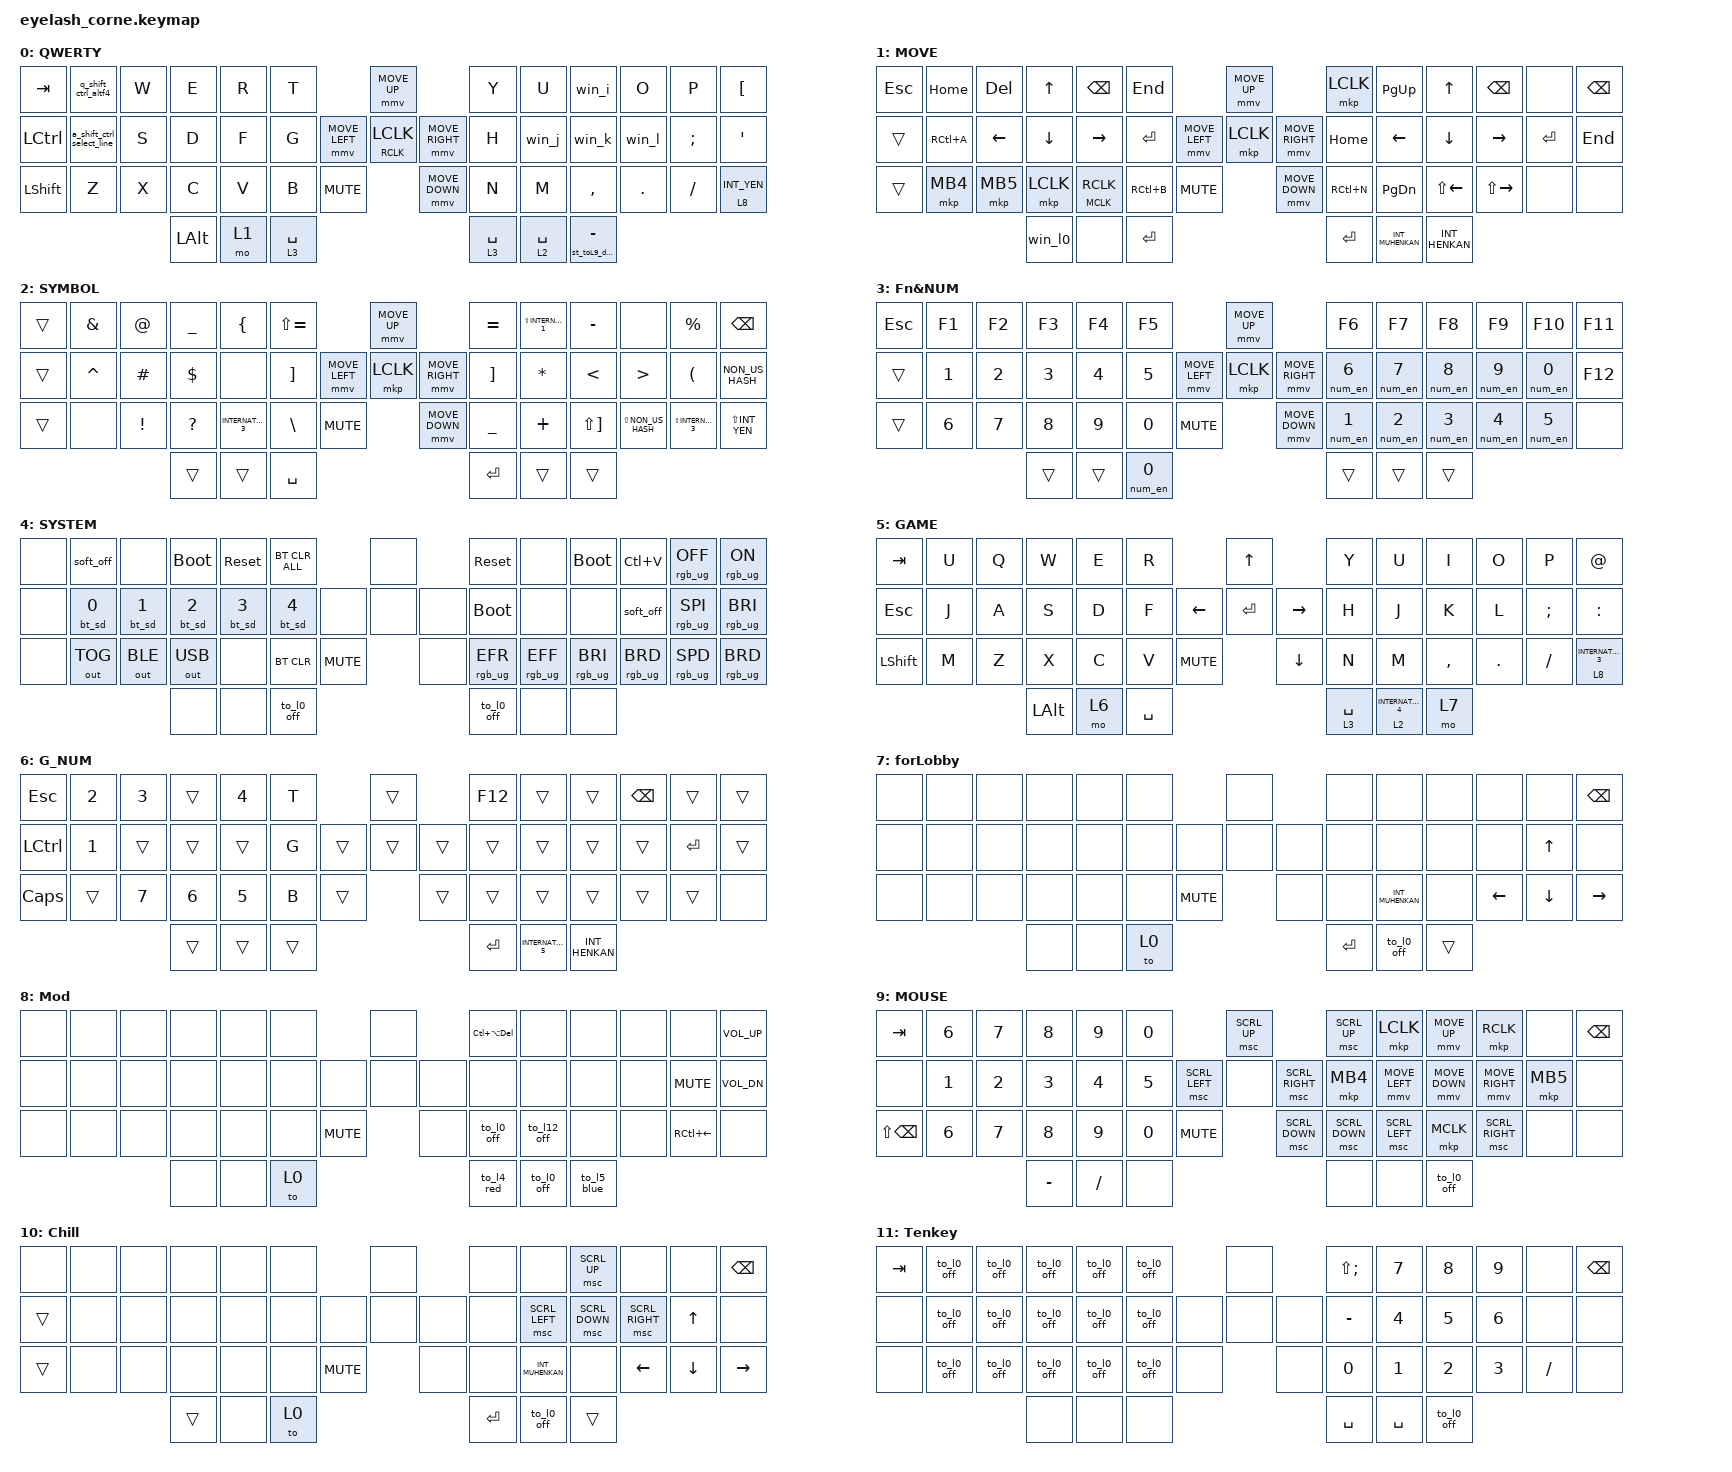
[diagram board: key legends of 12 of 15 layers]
#define ZMK_POINTING_DEFAULT_MOVE_VAL 1200  // 600
#define ZMK_POINTING_DEFAULT_SCRL_VAL 25    // 10
#define COLOR_RED RGB_COLOR_HSB(0, 100, 50)

#include <input/processors.dtsi>
#include <zephyr/dt-bindings/input/input-event-codes.h>
#include <behaviors/runtime-sensor-rotate.dtsi>
#include <behaviors.dtsi>
#include <dt-bindings/zmk/bt.h>
#include <dt-bindings/zmk/keys.h>
#include <dt-bindings/zmk/outputs.h>
#include <dt-bindings/zmk/pointing.h>
#include <dt-bindings/zmk/rgb.h>

&soft_off { hold-time-ms = <2000>; };

/ {
    macros {
        // Winキーを押した時にWinを保持したままLayer 0へ戻るマクロ

        win_l0: win_l0 {
            compatible = "zmk,behavior-macro";
            #binding-cells = <0>;
            wait-ms = <0>;
            tap-ms = <0>;
            bindings =
                <&macro_press>,
                <&kp LEFT_WIN &to 0>,
                <&macro_pause_for_release>,
                <&macro_release>,
                <&kp LEFT_WIN>;
        };

        // レイヤー4へ移動し、LEDをONにして赤くする

        to_l4_red: to_l4_red {
            compatible = "zmk,behavior-macro";
            #binding-cells = <0>;
            bindings = <&to 4 &rgb_ug COLOR_RED &rgb_ug RGB_ON>;
        };

        // レイヤー0(通常)に戻り、LEDをOFFにする

        to_l0_off: to_l0_off {
            compatible = "zmk,behavior-macro";
            #binding-cells = <0>;
            bindings = <&to 0 &rgb_ug RGB_OFF>;
        };

        // 【追加】レイヤー5へ移動し、LEDをONにして青くする（1秒後に自動消灯）

        to_l5_blue: to_l5_blue {
            compatible = "zmk,behavior-macro";
            #binding-cells = <0>;
            bindings = <&to 5>;
        };

        // 【追加】レイヤー7へ移動し、LEDをONにして紫にする（1秒後に自動消灯）

        to_l7_purple: to_l7_purple {
            compatible = "zmk,behavior-macro";
            #binding-cells = <0>;
            bindings = <&to 8>;

            // <&macro_wait_time 1000>,
            // <&rgb_ug RGB_OFF>;
        };

        // 【追加】レイヤー8へ移動し、LEDをONにしてオレンジにする

        to_l8_orange: to_l8_orange {
            compatible = "zmk,behavior-macro";
            #binding-cells = <0>;
            bindings = <&rgb_ug RGB_COLOR_HSB(7, 100, 50) &rgb_ug RGB_ON &to 9>;
        };

        // 【追加】レイヤー10へ移動し、LEDをONにして水色にする

        to_l10_light_blue: to_l10_light_blue {
            compatible = "zmk,behavior-macro";
            #binding-cells = <0>;
            bindings = <&rgb_ug RGB_COLOR_HSB(180, 100, 50) &rgb_ug RGB_ON &to 11>;
        };

        // レイヤー12(Mac)、LEDをOFFにする

        to_l12_off: to_l12_off {
            compatible = "zmk,behavior-macro";
            #binding-cells = <0>;
            bindings = <&to 12 &rgb_ug RGB_OFF>;
        };

        /* 1. 一連のキー送信を行うマクロの定義 (行選択マクロ)*/

        select_line: select_line {
            compatible = "zmk,behavior-macro";
            #binding-cells = <0>;

            // キューのディレイを0にして、Aが離される前に瞬時に終わらせる

            wait-ms = <0>;
            tap-ms = <0>;
            bindings =
                <&macro_tap>,
                <&kp HOME>,
                <&macro_press>,
                <&kp RSHFT>,
                <&macro_tap>,
                <&kp END>,
                <&macro_release>,
                <&kp RSHFT>;

            /* ④ Shiftキーを離す */
        };

        num_en: num_en {
            compatible = "zmk,behavior-macro-one-param";
            #binding-cells = <1>;
            wait-ms = <0>;
            tap-ms = <10>;
            bindings =
                <&macro_tap>,
                <&kp INT5 &kp LANG2 &macro_param_1to1 &kp MACRO_PLACEHOLDER>;
        };
    };

    behaviors {
        // Win(GUI)押下時だけ H/J/K/L を 矢印キー に変える mod-morph

        win_i: win_i {
            compatible = "zmk,behavior-mod-morph";
            #binding-cells = <0>;
            bindings = <&kp I>, <&kp UP>;

            mods = <(MOD_LGUI|MOD_RGUI)>;
        };

        win_j: win_j {
            compatible = "zmk,behavior-mod-morph";
            #binding-cells = <0>;
            bindings = <&kp J>, <&kp LEFT>;

            mods = <(MOD_LGUI|MOD_RGUI)>;
        };

        win_k: win_k {
            compatible = "zmk,behavior-mod-morph";
            #binding-cells = <0>;
            bindings = <&kp K>, <&kp DOWN>;

            mods = <(MOD_LGUI|MOD_RGUI)>;
        };

        win_l: win_l {
            compatible = "zmk,behavior-mod-morph";
            #binding-cells = <0>;
            bindings = <&kp L>, <&kp RIGHT>;

            mods = <(MOD_LGUI|MOD_RGUI)>;
        };

        td0: td0 {
            compatible = "zmk,behavior-tap-dance";
            display-name = "Shift/Caps Lock Tap Dance";
            #binding-cells = <0>;
            bindings = <&kp LEFT_SHIFT>, <&kp CAPS>;
        };

        rsr_vol: rsr_vol {
            compatible = "zmk,behavior-runtime-sensor-rotate";
            #sensor-binding-cells = <0>;
            tap-ms = <5>;
            cw-binding = <&kp C_VOL_UP>;
            ccw-binding = <&kp C_VOL_DN>;
        };

        rsr_trans: rsr_trans {
            compatible = "zmk,behavior-runtime-sensor-rotate";
            #sensor-binding-cells = <0>;
            tap-ms = <0>;
        };

        st_toL9_dt_toL8_tt_toL10: st_toL9_dt_toL8_tt_toL10 {
            compatible = "zmk,behavior-tap-dance";
            label = "ST_TOL9_DT_TOL8_TT_TOL10";
            #binding-cells = <0>;
            bindings = <&mo 10>, <&to_l8_orange>, <&to_l10_light_blue>;

            tapping-term-ms = <200>;
        };

        recent_key_yen: recent_key_yen {
            compatible = "zmk,behavior-hold-tap";
            #binding-cells = <2>;
            flavor = "hold-preferred";
            tapping-term-ms = <1>;
            require-prior-idle-ms = <1000>;
            bindings = <&st_toL9_dt_toL8_tt_toL10>, <&kp>;
        };

        // 既存の &lt の挙動自体をホールド優先に上書き

        lt: layer_tap {
            compatible = "zmk,behavior-hold-tap";
            label = "LAYER_TAP";
            #binding-cells = <2>;
            flavor = "hold-preferred";
            tapping-term-ms = <200>;
            quick-tap-ms = <150>;
            bindings = <&mo>, <&kp>;
        };

        shift_muhenkan: shift_muhenkan {
            compatible = "zmk,behavior-tap-dance";
            label = "SHIFT_MUHENKAN";
            #binding-cells = <0>;
            bindings = <&kp LEFT_SHIFT>, <&kp LEFT_SHIFT>, <&kp INT_MUHENKAN>;

            tapping-term-ms = <350>;
        };

        // Shift + Ctrl + Q → Alt + F4
        // Shift単独では通常のQ、Shift + Ctrl時だけAlt+F4

        q_shift_ctrl_altf4: q_shift_ctrl_altf4 {
            compatible = "zmk,behavior-mod-morph";
            #binding-cells = <0>;
            bindings = <&kp Q>, <&q_ctrl_altf4>;

            mods = <(MOD_LSFT)>;
            keep-mods = <(MOD_LSFT)>;
        };

        // Ctrl + Q → Q、Shift + Ctrl + Q → Alt + F4

        q_ctrl_altf4: q_ctrl_altf4 {
            compatible = "zmk,behavior-mod-morph";
            #binding-cells = <0>;
            bindings = <&kp Q>, <&kp LA(F4)>;

            mods = <(MOD_LCTL)>;
        };

        // Ctrl + Shift + A → select_line
        // Shift単独では通常のA
        // Ctrl + Shift時だけselect_line

        a_shift_ctrl_select_line: a_shift_ctrl_select_line {
            compatible = "zmk,behavior-mod-morph";
            #binding-cells = <0>;
            bindings = <&kp A>, <&a_ctrl_select_line>;

            mods = <(MOD_LSFT)>;
            keep-mods = <(MOD_LSFT)>;
        };

        // Ctrl + A → A、Shift + Ctrl + A → select_line

        a_ctrl_select_line: a_ctrl_select_line {
            compatible = "zmk,behavior-mod-morph";
            #binding-cells = <0>;
            bindings = <&kp A>, <&mask_select_line>;

            mods = <(MOD_LCTL)>;
        };

        mask_select_line: mask_select_line {
            compatible = "zmk,behavior-mask-mods";
            #binding-cells = <0>;
            bindings = <&select_line>;
            mods = <(MOD_LCTL | MOD_LSFT)>;
        };

        mouse_click: mouse_click {
            compatible = "zmk,behavior-hold-tap";
            #binding-cells = <2>;
            flavor = "hold-preferred";
            tapping-term-ms = <200>;
            bindings = <&mkp>, <&mkp>;
        };

        bt_sd: bt_select_disconnect {
            compatible = "zmk,behavior-bt-select-disconnect";
            #binding-cells = <1>;
        };
    };

    combos {
        compatible = "zmk,combos";

        task_manager {
            bindings = <&kp LS(LC(ESCAPE))>;
            key-positions = <0 13 28 43>;
        };

        /* 2. レイヤー制限付きコンボの定義 (行選択マクロ)*/

        combo_select_line {
            timeout-ms = <50>;

            /* ★ Ctrl、Shift、A に相当する3つのキー位置番号を指定します */

            key-positions = <13 28 14>;
            bindings = <&select_line>;

            /* ★ 通常レイヤー（例: 0番）のみで有効化する設定 */

            layers = <0>;
        };

        Combo_Muhenkan {
            bindings = <&kp INT_MUHENKAN>;
            key-positions = <17 16>;
            layers = <0>;
        };

        Combo_Henkan {
            bindings = <&kp INT_HENKAN>;
            key-positions = <23 24>;
            layers = <0>;
        };

        ComboESC {
            bindings = <&kp ESCAPE>;
            key-positions = <3 2>;
            layers = <0>;
        };

        Combo_Enter {
            bindings = <&kp ENTER>;
            key-positions = <25 26>;
            layers = <0>;
        };

        Combo_BS {
            bindings = <&kp BACKSPACE>;
            key-positions = <11 10>;
            layers = <0>;
        };

        Combo_Delete {
            bindings = <&kp BACKSPACE>;
            key-positions = <9 10>;
            layers = <0>;
        };

        Combo_FJ_Minus {
            bindings = <&kp MINUS>;
            key-positions = <17 23>;
        };

        Combo_HK_Minus {
            bindings = <&kp MINUS>;
            key-positions = <22 24>;
        };

        Combo_Eisu_forApple {
            bindings = <&kp LANG2>;
            key-positions = <17 16>;
            layers = <12>;
        };

        Combo_Kana_forApple {
            bindings = <&kp LANG1>;
            key-positions = <23 24>;
            layers = <12>;
        };
    };

    keymap {
        compatible = "zmk,keymap";

        DEFAULT_LAYER {
            display-name = "QWERTY";
            bindings = <
&kp TAB         &q_shift_ctrl_altf4        &kp W  &kp E         &kp R  &kp T                                      &mmv MOVE_UP                             &kp Y        &kp U        &win_i                   &kp O    &kp P     &kp LEFT_BRACKET
&kp LCTRL       &a_shift_ctrl_select_line  &kp S  &kp D         &kp F  &kp G                      &mmv MOVE_LEFT  &mouse_click RCLK LCLK  &mmv MOVE_RIGHT  &kp H        &win_j       &win_k                   &win_l   &kp SEMI  &kp SQT
&kp LEFT_SHIFT  &kp Z                      &kp X  &kp C         &kp V  &kp B        &kp C_MUTE                    &mmv MOVE_DOWN                           &kp N        &kp M        &kp COMMA                &kp DOT  &kp FSLH  &lt 8 INT_YEN
                                                  &kp LEFT_ALT  &mo 1  &lt 3 SPACE                                                                         &lt 3 SPACE  &lt 2 SPACE  &recent_key_yen 0 MINUS
            >;

            sensor-bindings = <&rsr_vol &rsr_trans>;
        };

        MOVE_LAYER {
            display-name = "MOVE";
            bindings = <
&kp ESC  &kp HOME   &kp DEL         &kp UP     &kp BACKSPACE           &kp END                                  &mmv MOVE_UP                     &mkp LCLK  &kp PG_UP         &kp UP_ARROW        &kp BACKSPACE  &none      &kp BSPC
&trans   &kp RC(A)  &kp LEFT_ARROW  &kp DOWN   &kp RIGHT_ARROW         &kp ENTER                &mmv MOVE_LEFT  &mkp LCLK       &mmv MOVE_RIGHT  &kp HOME   &kp LEFT          &kp DOWN            &kp RIGHT      &kp ENTER  &kp END
&trans   &mkp MB4   &mkp MB5        &mkp LCLK  &mouse_click MCLK RCLK  &kp RC(B)  &kp C_MUTE                    &mmv MOVE_DOWN                   &kp RC(N)  &kp PAGE_DOWN     &kp LS(LEFT_ARROW)  &kp LS(RIGHT)  &none      &none
                                    &win_l0    &none                   &kp ENTER                                                                 &kp ENTER  &kp INT_MUHENKAN  &kp INT_HENKAN
            >;

            sensor-bindings = <&rsr_vol &rsr_trans>;
        };

        SYMBOL_LAYER {
            display-name = "SYMBOL";
            bindings = <
&trans  &kp AMPERSAND  &kp AT    &kp UNDER     &kp LEFT_BRACE       &kp LS(EQUAL)                                    &mmv MOVE_UP                     &kp EQUAL          &kp LS(INTERNATIONAL_1)  &kp MINUS              &none                &kp PERCENT              &kp BSPC
&trans  &kp CARET      &kp HASH  &kp DOLLAR    &none                &kp RIGHT_BRACKET                &mmv MOVE_LEFT  &mkp LCLK       &mmv MOVE_RIGHT  &kp RIGHT_BRACKET  &kp ASTRK                &kp LESS_THAN          &kp GREATER_THAN     &kp LEFT_PARENTHESIS     &kp NON_US_HASH
&trans  &none          &kp EXCL  &kp QUESTION  &kp INTERNATIONAL_3  &kp BACKSLASH      &kp C_MUTE                    &mmv MOVE_DOWN                   &kp UNDER          &kp PLUS                 &kp LS(RIGHT_BRACKET)  &kp LS(NON_US_HASH)  &kp LS(INTERNATIONAL_3)  &kp LS(INT_YEN)
                                 &trans        &trans               &kp SPACE                                                                         &kp RET            &trans                   &trans
            >;

            sensor-bindings = <&rsr_vol &rsr_trans>;
        };

        NUM_LAYER {
            display-name = "Fn&NUM";
            bindings = <
&kp ESCAPE  &kp F1        &kp F2        &kp F3        &kp F4        &kp F5                                      &mmv MOVE_UP                     &kp F6            &kp F7            &kp F8            &kp F9            &kp F10     &kp F11
&trans      &kp N1        &kp NUMBER_2  &kp NUMBER_3  &kp NUMBER_4  &kp NUMBER_5                &mmv MOVE_LEFT  &mkp LCLK       &mmv MOVE_RIGHT  &num_en NUMBER_6  &num_en N7        &num_en N8        &num_en N9        &num_en N0  &kp F12
&trans      &kp NUMBER_6  &kp N7        &kp N8        &kp N9        &kp N0        &kp C_MUTE                    &mmv MOVE_DOWN                   &num_en NUMBER_1  &num_en NUMBER_2  &num_en NUMBER_3  &num_en NUMBER_4  &num_en N5  &none
                                        &trans        &trans        &num_en N0                                                                   &trans            &trans            &trans
            >;

            sensor-bindings = <&rsr_vol &rsr_trans>;
        };

        SYSTEM_LAYER {
            display-name = "SYSTEM";
            bindings = <
&none  &soft_off     &none         &bootloader   &sys_reset  &bt BT_CLR_ALL                       &none         &sys_reset       &none            &bootloader      &kp LC(V)        &rgb_ug RGB_OFF  &rgb_ug RGB_ON
&none  &bt_sd 0      &bt_sd 1      &bt_sd 2      &bt_sd 3    &bt_sd 4                      &none  &none  &none  &bootloader      &none            &none            &soft_off        &rgb_ug RGB_SPI  &rgb_ug RGB_BRI
&none  &out OUT_TOG  &out OUT_BLE  &out OUT_USB  &none       &bt BT_CLR      &kp C_MUTE           &none         &rgb_ug RGB_EFR  &rgb_ug RGB_EFF  &rgb_ug RGB_BRI  &rgb_ug RGB_BRD  &rgb_ug RGB_SPD  &rgb_ug RGB_BRD
                                   &none         &none       &to_l0_off                                         &to_l0_off       &none            &none
            >;

            sensor-bindings = <&rsr_vol>, <&rsr_trans>;
        };

        GameMain {
            display-name = "GAME";
            bindings = <
&kp TAB     &kp U  &kp Q  &kp W     &kp E  &kp R                              &kp UP                &kp Y        &kp U                  &kp I      &kp O    &kp P     &kp AT
&kp ESCAPE  &kp J  &kp A  &kp S     &kp D  &kp F                    &kp LEFT  &kp ENTER  &kp RIGHT  &kp H        &kp J                  &kp K      &kp L    &kp SEMI  &kp COLON
&kp LSHFT   &kp M  &kp Z  &kp X     &kp C  &kp V      &kp C_MUTE              &kp DOWN              &kp N        &kp M                  &kp COMMA  &kp DOT  &kp FSLH  &lt 8 INTERNATIONAL_3
                          &kp LALT  &mo 6  &kp SPACE                                                &lt 3 SPACE  &lt 2 INTERNATIONAL_4  &mo 7
            >;

            sensor-bindings = <&rsr_vol>, <&rsr_trans>;
        };

        GameSub {
            display-name = "G_NUM";
            bindings = <
&kp ESC       &kp N2  &kp NUMBER_3  &trans        &kp NUMBER_4  &kp T                     &trans          &kp F12    &trans               &trans          &kp BACKSPACE  &trans     &trans
&kp LCTRL     &kp N1  &trans        &trans        &trans        &kp G             &trans  &trans  &trans  &trans     &trans               &trans          &trans         &kp ENTER  &trans
&kp CAPSLOCK  &trans  &kp N7        &kp NUMBER_6  &kp N5        &kp B   &trans            &trans          &trans     &trans               &trans          &trans         &trans     &none
                                    &trans        &trans        &trans                                    &kp ENTER  &kp INTERNATIONAL_5  &kp INT_HENKAN
            >;

            sensor-bindings = <&rsr_vol>, <&rsr_trans>;
        };

        GameAssist {
            display-name = "forLobby";
            bindings = <
&none  &none  &none  &none  &none  &none                       &none         &none      &none             &none   &none           &none         &kp BACKSPACE
&none  &none  &none  &none  &none  &none                &none  &none  &none  &none      &none             &none   &none           &kp UP_ARROW  &none
&none  &none  &none  &none  &none  &none  &kp C_MUTE           &none         &none      &kp INT_MUHENKAN  &none   &kp LEFT_ARROW  &kp DOWN      &kp RIGHT
                     &none  &none  &to 0                                     &kp ENTER  &to_l0_off        &trans
            >;

            sensor-bindings = <&rsr_vol>, <&rsr_trans>;
        };

        MOD_LAYER {
            display-name = "Mod";
            bindings = <
&none  &none  &none  &none  &none  &none                       &none         &kp LC(LA(DELETE))  &none        &none        &none  &none               &kp C_VOLUME_UP
&none  &none  &none  &none  &none  &none                &none  &none  &none  &none               &none        &none        &none  &kp C_MUTE          &kp C_VOL_DN
&none  &none  &none  &none  &none  &none  &kp C_MUTE           &none         &to_l0_off          &to_l12_off  &none        &none  &kp RC(LEFT_ARROW)  &none
                     &none  &none  &to 0                                     &to_l4_red          &to_l0_off   &to_l5_blue
            >;

            sensor-bindings = <&rsr_vol>, <&rsr_trans>;
        };

        MOUSE_LAYER {
            display-name = "MOUSE";
            bindings = <
&kp TAB            &kp N6  &kp N7  &kp N8     &kp N9    &kp N0                                &msc SCRL_UP                     &msc SCRL_UP    &mkp LCLK       &mmv MOVE_UP    &mkp RCLK        &none     &kp BACKSPACE
&none              &kp N1  &kp N2  &kp N3     &kp N4    &kp N5                &msc SCRL_LEFT  &none           &msc SCRL_RIGHT  &mkp MB4        &mmv MOVE_LEFT  &mmv MOVE_DOWN  &mmv MOVE_RIGHT  &mkp MB5  &none
&kp LS(BACKSPACE)  &kp N6  &kp N7  &kp N8     &kp N9    &kp N0  &kp C_MUTE                    &msc SCRL_DOWN                   &msc SCRL_DOWN  &msc SCRL_LEFT  &mkp MCLK       &msc SCRL_RIGHT  &none     &none
                                   &kp MINUS  &kp FSLH  &none                                                                  &none           &none           &to_l0_off
            >;

            sensor-bindings = <&rsr_vol>, <&rsr_trans>;
        };

        ONEHAND_LAYER {
            display-name = "Chill";
            bindings = <
&none   &none  &none  &none   &none  &none                       &none         &none      &none             &msc SCRL_UP    &none            &none         &kp BACKSPACE
&trans  &none  &none  &none   &none  &none                &none  &none  &none  &none      &msc SCRL_LEFT    &msc SCRL_DOWN  &msc SCRL_RIGHT  &kp UP_ARROW  &none
&trans  &none  &none  &none   &none  &none  &kp C_MUTE           &none         &none      &kp INT_MUHENKAN  &none           &kp LEFT_ARROW   &kp DOWN      &kp RIGHT
                      &trans  &none  &to 0                                     &kp ENTER  &to_l0_off        &trans
            >;

            sensor-bindings = <&rsr_vol>, <&rsr_trans>;
        };

        TENKEY_LAYER {
            bindings = <
&kp TAB  &to_l0_off  &to_l0_off  &to_l0_off  &to_l0_off  &to_l0_off                  &none         &kp LS(SEMICOLON)  &kp N7     &kp N8      &kp N9  &none     &kp BSPC
&none    &to_l0_off  &to_l0_off  &to_l0_off  &to_l0_off  &to_l0_off           &none  &none  &none  &kp MINUS          &kp N4     &kp N5      &kp N6  &none     &none
&none    &to_l0_off  &to_l0_off  &to_l0_off  &to_l0_off  &to_l0_off  &none           &none         &kp N0             &kp N1     &kp N2      &kp N3  &kp FSLH  &none
                                 &none       &none       &none                                     &kp SPACE          &kp SPACE  &to_l0_off
            >;

            label = "Tenkey";
        };

        MAC_DEFAULT {
            display-name = "MacDefault";
            bindings = <
&kp TAB         &kp Q  &kp W  &kp E             &kp R   &kp T                                      &mmv MOVE_UP                             &kp Y        &kp U         &win_i                   &kp O    &kp P     &kp LEFT_BRACKET
&kp LCTRL       &kp A  &kp S  &kp D             &kp F   &kp G                      &mmv MOVE_LEFT  &mouse_click RCLK LCLK  &mmv MOVE_RIGHT  &kp H        &win_j        &win_k                   &win_l   &kp SEMI  &kp SQT
&kp LEFT_SHIFT  &kp Z  &kp X  &kp C             &kp V   &kp B        &kp C_MUTE                    &mmv MOVE_DOWN                           &kp N        &kp M         &kp COMMA                &kp DOT  &kp FSLH  &lt 8 INT_YEN
                              &kp LEFT_COMMAND  &mo 13  &lt 3 SPACE                                                                         &lt 3 SPACE  &lt 13 SPACE  &recent_key_yen 0 MINUS
            >;

            sensor-bindings = <&rsr_vol>, <&rsr_trans>;
        };

        MAC_MOVE {
            display-name = "MacMove";
            bindings = <
&kp TAB         &kp Q  &kp W  &kp E         &kp R   &kp T                                      &mmv MOVE_UP                             &kp Y        &kp U        &win_i                   &kp O    &kp P     &kp LEFT_BRACKET
&kp LCTRL       &kp A  &kp S  &kp D         &kp F   &kp G                      &mmv MOVE_LEFT  &mouse_click RCLK LCLK  &mmv MOVE_RIGHT  &kp H        &win_j       &win_k                   &win_l   &kp SEMI  &kp SQT
&kp LEFT_SHIFT  &kp Z  &kp X  &kp C         &kp V   &kp B        &kp C_MUTE                    &mmv MOVE_DOWN                           &kp N        &kp M        &kp COMMA                &kp DOT  &kp FSLH  &lt 8 INT_YEN
                              &kp LEFT_ALT  &mo 12  &lt 3 SPACE                                                                         &lt 3 SPACE  &lt 2 SPACE  &recent_key_yen 0 MINUS
            >;

            sensor-bindings = <&rsr_vol>, <&rsr_trans>;
        };

        MAC_SYMBOL {
            display-name = "MacSymbol";
            bindings = <
&trans  &kp LS(N7)  &kp N2    &kp UNDER     &kp LS(LEFT_BRACKET)  &kp LS(EQUAL)                                    &mmv MOVE_UP                     &kp EQUAL  &kp LS(INTERNATIONAL_1)  &kp MINUS              &none                      &kp PERCENT          &kp BSPC
&trans  &kp LS(N6)  &kp HASH  &kp DOLLAR    &none                 &kp RIGHT_BRACKET                &mmv MOVE_LEFT  &mkp LCLK       &mmv MOVE_RIGHT  &kp RBKT   &kp LS(N8)               &kp LESS_THAN          &kp GREATER_THAN           &kp LS(N9)           &kp RIGHT_BRACKET
&trans  &none       &kp EXCL  &kp QUESTION  &kp INTERNATIONAL_3   &kp BACKSLASH      &kp C_MUTE                    &mmv MOVE_DOWN                   &kp UNDER  &kp PLUS                 &kp LS(RIGHT_BRACKET)  &kp LS(RIGHT_PARENTHESIS)  &kp INTERNATIONAL_1  &kp INT_YEN
                              &trans        &trans                &kp SPACE                                                                         &kp RET    &trans                   &trans
            >;

            sensor-bindings = <&rsr_vol>, <&rsr_trans>;
        };
    };
};
